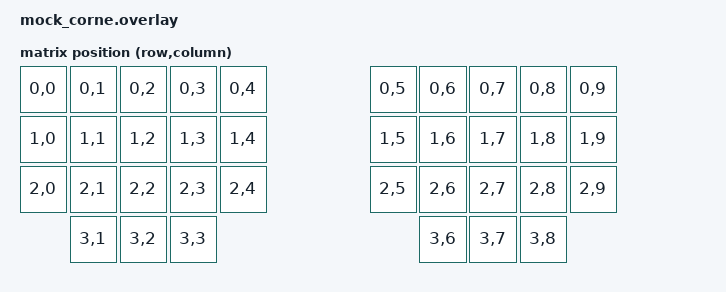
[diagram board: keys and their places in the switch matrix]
/* Generated by remappr — ZMK physical layout for Mock Corne.
 * Key geometry + a geometry-DERIVED matrix-transform are generated.
 * Remaining hardware nodes (kscan, pinctrl, backlight/underglow
 * drivers) are board-specific — keep them in your board/shield overlay.
 * The matrix-transform RC() map is a scaffold from physical position,
 * NOT the real kscan wiring — verify it before flashing. */
#include <physical_layouts.dtsi>
#include <dt-bindings/zmk/matrix_transform.h>

/ {
    physical_layout_default: physical_layout_default {
        compatible = "zmk,physical-layout";
        display-name = "Mock Corne";
        transform = <&default_transform>;
        keys
            = <&key_physical_attrs 100 100 0 0 0 0 0>
            , <&key_physical_attrs 100 100 100 0 0 0 0>
            , <&key_physical_attrs 100 100 200 0 0 0 0>
            , <&key_physical_attrs 100 100 300 0 0 0 0>
            , <&key_physical_attrs 100 100 400 0 0 0 0>
            , <&key_physical_attrs 100 100 0 100 0 0 0>
            , <&key_physical_attrs 100 100 100 100 0 0 0>
            , <&key_physical_attrs 100 100 200 100 0 0 0>
            , <&key_physical_attrs 100 100 300 100 0 0 0>
            , <&key_physical_attrs 100 100 400 100 0 0 0>
            , <&key_physical_attrs 100 100 0 200 0 0 0>
            , <&key_physical_attrs 100 100 100 200 0 0 0>
            , <&key_physical_attrs 100 100 200 200 0 0 0>
            , <&key_physical_attrs 100 100 300 200 0 0 0>
            , <&key_physical_attrs 100 100 400 200 0 0 0>
            , <&key_physical_attrs 100 100 100 300 0 0 0>
            , <&key_physical_attrs 100 100 200 300 0 0 0>
            , <&key_physical_attrs 100 100 300 300 0 0 0>
            , <&key_physical_attrs 100 100 700 0 0 0 0>
            , <&key_physical_attrs 100 100 800 0 0 0 0>
            , <&key_physical_attrs 100 100 900 0 0 0 0>
            , <&key_physical_attrs 100 100 1000 0 0 0 0>
            , <&key_physical_attrs 100 100 1100 0 0 0 0>
            , <&key_physical_attrs 100 100 700 100 0 0 0>
            , <&key_physical_attrs 100 100 800 100 0 0 0>
            , <&key_physical_attrs 100 100 900 100 0 0 0>
            , <&key_physical_attrs 100 100 1000 100 0 0 0>
            , <&key_physical_attrs 100 100 1100 100 0 0 0>
            , <&key_physical_attrs 100 100 700 200 0 0 0>
            , <&key_physical_attrs 100 100 800 200 0 0 0>
            , <&key_physical_attrs 100 100 900 200 0 0 0>
            , <&key_physical_attrs 100 100 1000 200 0 0 0>
            , <&key_physical_attrs 100 100 1100 200 0 0 0>
            , <&key_physical_attrs 100 100 800 300 0 0 0>
            , <&key_physical_attrs 100 100 900 300 0 0 0>
            , <&key_physical_attrs 100 100 1000 300 0 0 0>
            ;
    };

    default_transform: keymap_transform_0 {
        compatible = "zmk,matrix-transform";
        /* DERIVED from key geometry — confirm against your kscan. */
        columns = <10>;
        rows = <4>;
        map = <
            RC(0,0) RC(0,1) RC(0,2) RC(0,3) RC(0,4)
            RC(1,0) RC(1,1) RC(1,2) RC(1,3) RC(1,4)
            RC(2,0) RC(2,1) RC(2,2) RC(2,3) RC(2,4)
            RC(3,1) RC(3,2) RC(3,3)
            RC(0,5) RC(0,6) RC(0,7) RC(0,8) RC(0,9)
            RC(1,5) RC(1,6) RC(1,7) RC(1,8) RC(1,9)
            RC(2,5) RC(2,6) RC(2,7) RC(2,8) RC(2,9)
            RC(3,6) RC(3,7) RC(3,8)
        >;
    };
};

/* ─────────────────────────────────────────────────────────────────────
 * NOT GENERATED by remappr — board-specific hardware, add from your
 * board/shield overlay (these are wiring, not keymap):
 *
 *   • kscan          — matrix/direct GPIO scan + row/col gpios
 *   • chosen         — zmk,kscan / zmk,physical-layout / zmk,matrix-transform
 *   • &gpio / diode-direction, debounce timings
 *   • pinctrl / pins — SoC pin mux for the kscan GPIOs
 *   • underglow / backlight / RGB LED drivers (e.g. &led_strip)
 *   • encoders (EC11 sensors) + sensor-channel wiring
 *   • power / battery / ext-power control nodes
 *   • display, pointing device, or other peripheral nodes
 *
 * Also re-check the matrix-transform RC() map above against your real
 * kscan — it is derived from physical position, not electrical wiring.
 * ───────────────────────────────────────────────────────────────────── */
